# nrf9220_cellrf register map
Vendor: Nordic Semiconductor; Series: nRF92; File version: 1
CPU: CM0 r0p0, little endian, no MPU, no FPU, 2 interrupt priority bits, 33 interrupts
Registers are 32-bit, read-write, reset 0x0 unless marked. A register's access mark holds for its fields unless they carry their own. Offsets are from the block's base; [hi:lo] are bit positions; {n}, {i} and the like mark numbered series; 'fields as' and 'values as' point back to an identical list.

## RXDFE (part 1 of 2) — HALTI_RX_register_map AhmaRx Digital control register map Karhu Rx Analog control register map AhmaRx Digital control register map
Base 0x46130000
0x00 TASKS_RX_START_DIG wo — Starts RX digital filtering.
  [0] TASKS_RX_START_DIG
    1=Trigger task
0x04 TASKS_RX_STOP_DIG wo — Stops RX digital filtering.
  [0] TASKS_RX_STOP_DIG
    1=Trigger task
0x08 TASKS_RX_START_DATA wo — Starts data transfer.
  [0] TASKS_RX_START_DATA
    1=Trigger task
0x0C TASKS_RX_STOP_DATA wo — Stops data transfer.
  [0] TASKS_RX_STOP_DATA
    1=Trigger task
0x10 TASKS_RX_START_NBPM wo — Starts narrow band power measurement.
  [0] TASKS_RX_START_NBPM
    1=Trigger task
0x14 TASKS_RX_START_WBPM wo — Starts wide band power measurement.
  [0] TASKS_RX_START_WBPM
    1=Trigger task
0x18 TASKS_RX_CAPT_SAMPLE_CNT_0 wo — Captures sample counter value to RX_SAMPLE_CNT_CAPT_0 register.
  [0] TASKS_RX_CAPT_SAMPLE_CNT_0
    1=Trigger task
0x1C TASKS_RX_CAPT_SAMPLE_CNT_1 wo — Captures sample counter value to RX_SAMPLE_CNT_CAPT_1 register.
  [0] TASKS_RX_CAPT_SAMPLE_CNT_1
    1=Trigger task
0x20 TASKS_RX_LATCHREADREG wo — Latches set of read-only registers.
  [0] TASKS_RX_LATCHREADREG
    1=Trigger task
0x24 TASKS_WIFI_CLEARIQENERGYDET wo — Clears the IQ energy detect signal monitoring flip-flop.
  [0] TASKS_WIFI_CLEARIQENERGYDET
    1=Trigger task
0x28 TASKS_WIFI_CLEARSIGNALDETGN wo — Clears the Wi-Fi g/n signal detect signal monitoring flip-flop.
  [0] TASKS_WIFI_CLEARSIGNALDETGN
    1=Trigger task
0x2C TASKS_WIFI_CLEARSIGNALDETB wo — Clears the Wi-Fi b signal detect signal monitoring flip-flop.
  [0] TASKS_WIFI_CLEARSIGNALDETB
    1=Trigger task
0x30 TASKS_WIFI_CLEARSIGNALDET wo — Clears the Wi-Fi signal detect signal monitoring flip-flop.
  [0] TASKS_WIFI_CLEARSIGNALDET
    1=Trigger task
0x34 TASKS_WIFI_CLEARRFGAINDOWN wo — Clears the RF gain down signal monitoring flip-flop.
  [0] TASKS_WIFI_CLEARRFGAINDOWN
    1=Trigger task
0x38 TASKS_WIFI_SNAPSHOTIQENERGYDET wo — Takes a snapshot of the IQ energy detect signal.
  [0] TASKS_WIFI_SNAPSHOTIQENERGYDET
    1=Trigger task
0x3C TASKS_WIFI_SNAPSHOTSIGNALDETGN wo — Takes a snapshot of the Wi-Fi g/n signal detect signal.
  [0] TASKS_WIFI_SNAPSHOTSIGNALDETGN
    1=Trigger task
0x40 TASKS_WIFI_SNAPSHOTSIGNALDETB wo — Takes a snapshot of the Wi-Fi b signal detect signal.
  [0] TASKS_WIFI_SNAPSHOTSIGNALDETB
    1=Trigger task
0x44 TASKS_WIFI_SNAPSHOTSIGNALDET wo — Takes a snapshot of the Wi-Fi signal detect signal.
  [0] TASKS_WIFI_SNAPSHOTSIGNALDET
    1=Trigger task
0x48 TASKS_WIFI_SNAPSHOTRFGAINDOWN wo — Takes a snapshot of the RF gain down signal.
  [0] TASKS_WIFI_SNAPSHOTRFGAINDOWN
    1=Trigger task
0x4C TASKS_WIFI_CLEARIQSYNCDET wo — Clears the IQ sync detect signal monitoring flip-flop.
  [0] TASKS_WIFI_CLEARIQSYNCDET
    1=Trigger task
0x50 TASKS_WIFI_SNAPSHOTIQSYNCDET wo — Takes a snapshot of the IQ sync detect signal.
  [0] TASKS_WIFI_SNAPSHOTIQSYNCDET
    1=Trigger task
0x54 TASKS_WIFI_CLEARIQSYNCMAX wo — Clears the max value of IQ sync.
  [0] TASKS_WIFI_CLEARIQSYNCMAX
    1=Trigger task
0x58 TASKS_RX_CAPT_SAMPLE_CNT_2 wo — Captures sample counter value to RX_SAMPLE_CNT_CAPT_2 register.
  [0] TASKS_RX_CAPT_SAMPLE_CNT_2
    1=Trigger task
0x5C TASKS_RX_CAPT_SAMPLE_CNT_3 wo — Captures sample counter value to RX_SAMPLE_CNT_CAPT_3 register.
  [0] TASKS_RX_CAPT_SAMPLE_CNT_3
    1=Trigger task
0x60 TASKS_RX_STOP_NBPM wo — Stops narrow band power measurement.
  [0] TASKS_RX_STOP_NBPM
    1=Trigger task
0x64 TASKS_RX_STOP_WBPM wo — Stops wide band power measurement.
  [0] TASKS_RX_STOP_WBPM
    1=Trigger task
0x68 TASKS_WIFI_CLEARIQENERGYDETWB wo — Clears the wide band IQ energy detect signal monitoring flip-flop.
  [0] TASKS_WIFI_CLEARIQENERGYDETWB
    1=Trigger task
0x6C TASKS_WIFI_SNAPSHOTIQENERGYDETWB wo — Takes a snapshot of the wide band IQ energy detect signal.
  [0] TASKS_WIFI_SNAPSHOTIQENERGYDETWB
    1=Trigger task
0x78 TASKS_WIFI_STARTDATAB wo — Starts RX Wi-Fi b data transfer.
  [0] TASKS_WIFI_STARTDATAB
    1=Trigger task
0x7C TASKS_WIFI_STOPDATAB wo — Stops RX Wi-Fi b data transfer.
  [0] TASKS_WIFI_STOPDATAB
    1=Trigger task
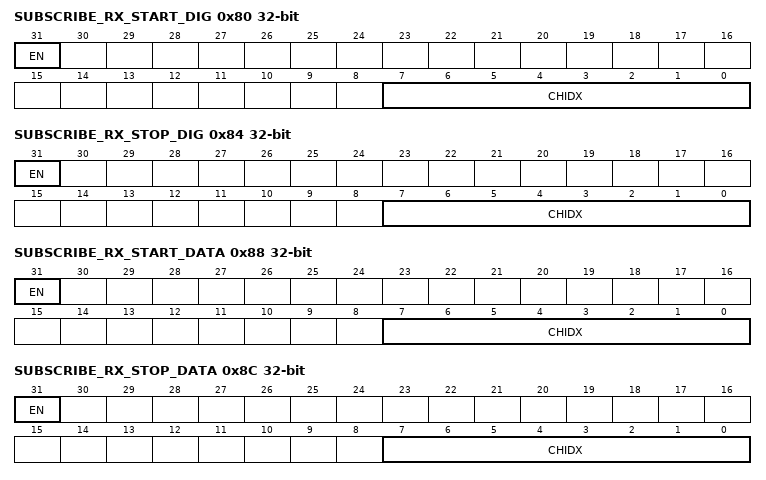
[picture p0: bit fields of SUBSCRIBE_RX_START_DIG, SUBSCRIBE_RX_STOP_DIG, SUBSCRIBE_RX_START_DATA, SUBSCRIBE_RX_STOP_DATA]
0x80 SUBSCRIBE_RX_START_DIG — Subscribe configuration for task RX_START_DIG
  [31] EN
    0=Disabled (Disable subscription); 1=Enabled (Enable subscription)
  [7:0] CHIDX — DPPI channel that task RX_START_DIG will subscribe to
0x84 SUBSCRIBE_RX_STOP_DIG — Subscribe configuration for task RX_STOP_DIG
  [31] EN
    values as SUBSCRIBE_RX_START_DIG.EN
  [7:0] CHIDX — DPPI channel that task RX_STOP_DIG will subscribe to
0x88 SUBSCRIBE_RX_START_DATA — Subscribe configuration for task RX_START_DATA
  [31] EN
    values as SUBSCRIBE_RX_START_DIG.EN
  [7:0] CHIDX — DPPI channel that task RX_START_DATA will subscribe to
0x8C SUBSCRIBE_RX_STOP_DATA — Subscribe configuration for task RX_STOP_DATA
  [31] EN
    values as SUBSCRIBE_RX_START_DIG.EN
  [7:0] CHIDX — DPPI channel that task RX_STOP_DATA will subscribe to
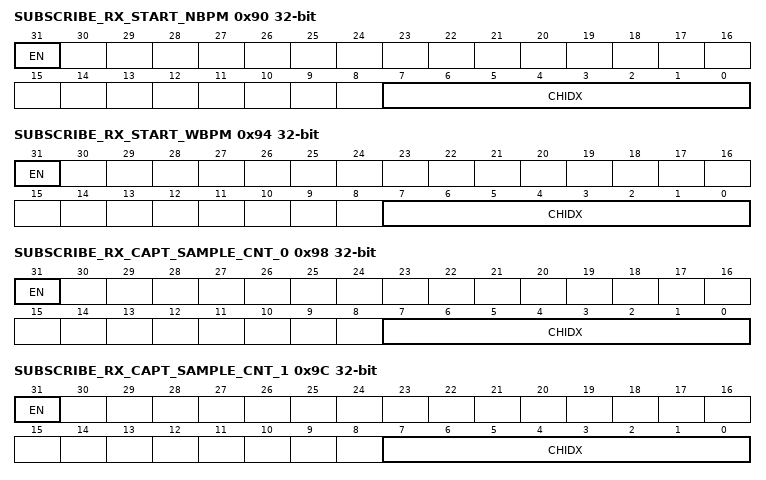
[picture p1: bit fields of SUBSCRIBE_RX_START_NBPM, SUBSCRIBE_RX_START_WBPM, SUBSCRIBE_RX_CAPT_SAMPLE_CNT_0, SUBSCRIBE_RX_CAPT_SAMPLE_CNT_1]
0x90 SUBSCRIBE_RX_START_NBPM — Subscribe configuration for task RX_START_NBPM
  [31] EN
    values as SUBSCRIBE_RX_START_DIG.EN
  [7:0] CHIDX — DPPI channel that task RX_START_NBPM will subscribe to
0x94 SUBSCRIBE_RX_START_WBPM — Subscribe configuration for task RX_START_WBPM
  [31] EN
    values as SUBSCRIBE_RX_START_DIG.EN
  [7:0] CHIDX — DPPI channel that task RX_START_WBPM will subscribe to
0x98 SUBSCRIBE_RX_CAPT_SAMPLE_CNT_0 — Subscribe configuration for task RX_CAPT_SAMPLE_CNT_0
  [31] EN
    values as SUBSCRIBE_RX_START_DIG.EN
  [7:0] CHIDX — DPPI channel that task RX_CAPT_SAMPLE_CNT_0 will subscribe to
0x9C SUBSCRIBE_RX_CAPT_SAMPLE_CNT_1 — Subscribe configuration for task RX_CAPT_SAMPLE_CNT_1
  [31] EN
    values as SUBSCRIBE_RX_START_DIG.EN
  [7:0] CHIDX — DPPI channel that task RX_CAPT_SAMPLE_CNT_1 will subscribe to
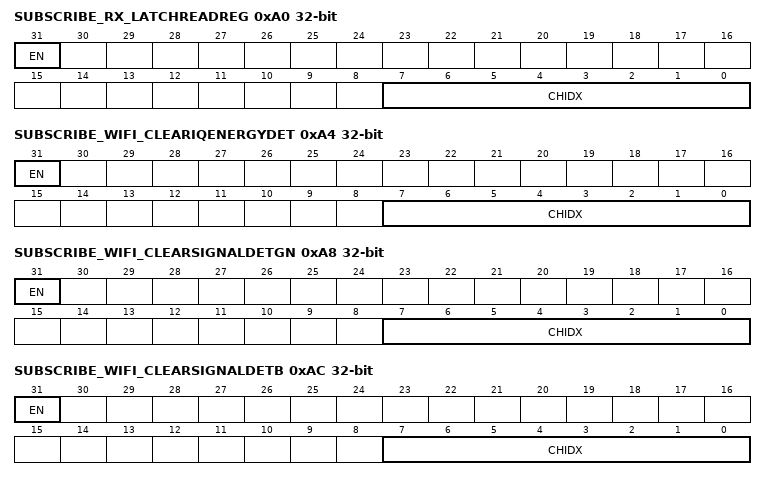
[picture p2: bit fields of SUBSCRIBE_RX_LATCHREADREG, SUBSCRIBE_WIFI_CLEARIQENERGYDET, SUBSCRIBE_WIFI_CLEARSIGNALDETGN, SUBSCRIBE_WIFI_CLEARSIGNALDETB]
0xA0 SUBSCRIBE_RX_LATCHREADREG — Subscribe configuration for task RX_LATCHREADREG
  [31] EN
    values as SUBSCRIBE_RX_START_DIG.EN
  [7:0] CHIDX — DPPI channel that task RX_LATCHREADREG will subscribe to
0xA4 SUBSCRIBE_WIFI_CLEARIQENERGYDET — Subscribe configuration for task WIFI_CLEARIQENERGYDET
  [31] EN
    values as SUBSCRIBE_RX_START_DIG.EN
  [7:0] CHIDX — DPPI channel that task WIFI_CLEARIQENERGYDET will subscribe to
0xA8 SUBSCRIBE_WIFI_CLEARSIGNALDETGN — Subscribe configuration for task WIFI_CLEARSIGNALDETGN
  [31] EN
    values as SUBSCRIBE_RX_START_DIG.EN
  [7:0] CHIDX — DPPI channel that task WIFI_CLEARSIGNALDETGN will subscribe to
0xAC SUBSCRIBE_WIFI_CLEARSIGNALDETB — Subscribe configuration for task WIFI_CLEARSIGNALDETB
  [31] EN
    values as SUBSCRIBE_RX_START_DIG.EN
  [7:0] CHIDX — DPPI channel that task WIFI_CLEARSIGNALDETB will subscribe to
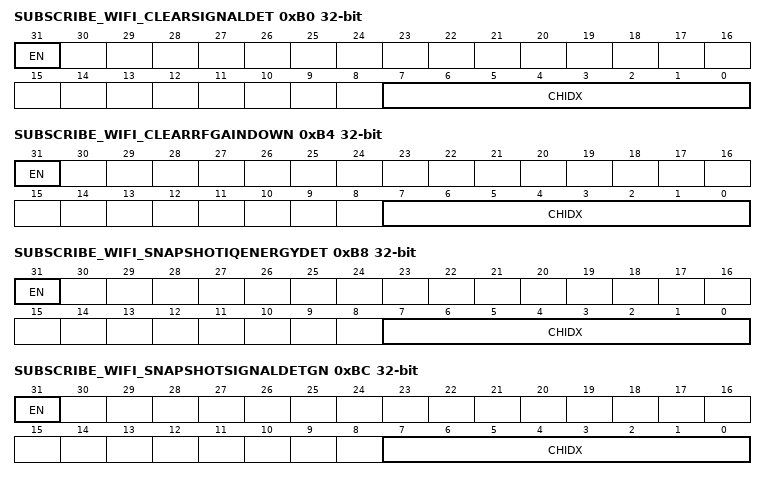
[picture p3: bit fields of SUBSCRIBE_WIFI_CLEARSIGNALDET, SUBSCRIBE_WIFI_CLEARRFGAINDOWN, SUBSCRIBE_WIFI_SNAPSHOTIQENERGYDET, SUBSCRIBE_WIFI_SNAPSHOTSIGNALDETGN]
0xB0 SUBSCRIBE_WIFI_CLEARSIGNALDET — Subscribe configuration for task WIFI_CLEARSIGNALDET
  [31] EN
    values as SUBSCRIBE_RX_START_DIG.EN
  [7:0] CHIDX — DPPI channel that task WIFI_CLEARSIGNALDET will subscribe to
0xB4 SUBSCRIBE_WIFI_CLEARRFGAINDOWN — Subscribe configuration for task WIFI_CLEARRFGAINDOWN
  [31] EN
    values as SUBSCRIBE_RX_START_DIG.EN
  [7:0] CHIDX — DPPI channel that task WIFI_CLEARRFGAINDOWN will subscribe to
0xB8 SUBSCRIBE_WIFI_SNAPSHOTIQENERGYDET — Subscribe configuration for task WIFI_SNAPSHOTIQENERGYDET
  [31] EN
    values as SUBSCRIBE_RX_START_DIG.EN
  [7:0] CHIDX — DPPI channel that task WIFI_SNAPSHOTIQENERGYDET will subscribe to
0xBC SUBSCRIBE_WIFI_SNAPSHOTSIGNALDETGN — Subscribe configuration for task WIFI_SNAPSHOTSIGNALDETGN
  [31] EN
    values as SUBSCRIBE_RX_START_DIG.EN
  [7:0] CHIDX — DPPI channel that task WIFI_SNAPSHOTSIGNALDETGN will subscribe to
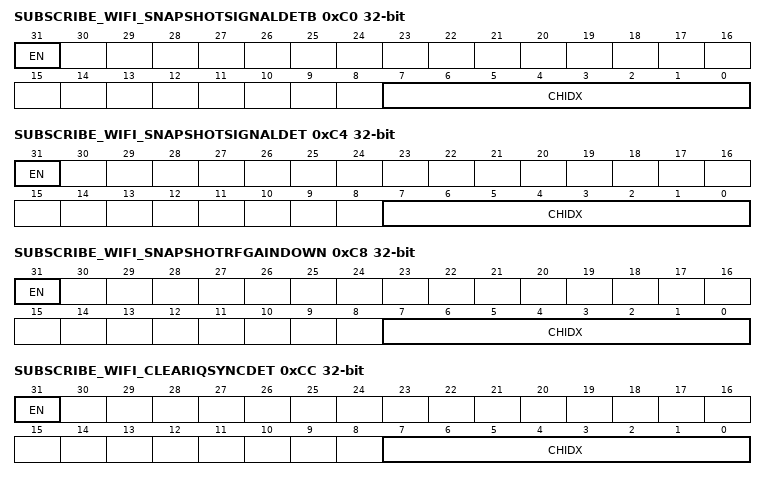
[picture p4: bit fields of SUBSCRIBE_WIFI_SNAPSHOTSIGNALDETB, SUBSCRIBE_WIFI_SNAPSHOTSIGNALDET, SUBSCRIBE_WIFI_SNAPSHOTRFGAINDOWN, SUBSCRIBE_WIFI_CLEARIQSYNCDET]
0xC0 SUBSCRIBE_WIFI_SNAPSHOTSIGNALDETB — Subscribe configuration for task WIFI_SNAPSHOTSIGNALDETB
  [31] EN
    values as SUBSCRIBE_RX_START_DIG.EN
  [7:0] CHIDX — DPPI channel that task WIFI_SNAPSHOTSIGNALDETB will subscribe to
0xC4 SUBSCRIBE_WIFI_SNAPSHOTSIGNALDET — Subscribe configuration for task WIFI_SNAPSHOTSIGNALDET
  [31] EN
    values as SUBSCRIBE_RX_START_DIG.EN
  [7:0] CHIDX — DPPI channel that task WIFI_SNAPSHOTSIGNALDET will subscribe to
0xC8 SUBSCRIBE_WIFI_SNAPSHOTRFGAINDOWN — Subscribe configuration for task WIFI_SNAPSHOTRFGAINDOWN
  [31] EN
    values as SUBSCRIBE_RX_START_DIG.EN
  [7:0] CHIDX — DPPI channel that task WIFI_SNAPSHOTRFGAINDOWN will subscribe to
0xCC SUBSCRIBE_WIFI_CLEARIQSYNCDET — Subscribe configuration for task WIFI_CLEARIQSYNCDET
  [31] EN
    values as SUBSCRIBE_RX_START_DIG.EN
  [7:0] CHIDX — DPPI channel that task WIFI_CLEARIQSYNCDET will subscribe to
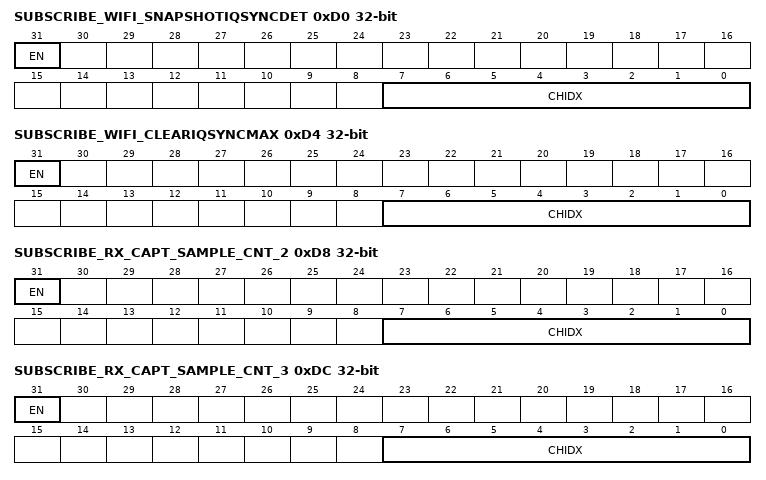
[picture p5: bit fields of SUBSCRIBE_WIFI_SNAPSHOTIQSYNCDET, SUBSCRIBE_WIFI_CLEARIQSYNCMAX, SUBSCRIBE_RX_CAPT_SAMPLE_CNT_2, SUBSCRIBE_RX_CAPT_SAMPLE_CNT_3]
0xD0 SUBSCRIBE_WIFI_SNAPSHOTIQSYNCDET — Subscribe configuration for task WIFI_SNAPSHOTIQSYNCDET
  [31] EN
    values as SUBSCRIBE_RX_START_DIG.EN
  [7:0] CHIDX — DPPI channel that task WIFI_SNAPSHOTIQSYNCDET will subscribe to
0xD4 SUBSCRIBE_WIFI_CLEARIQSYNCMAX — Subscribe configuration for task WIFI_CLEARIQSYNCMAX
  [31] EN
    values as SUBSCRIBE_RX_START_DIG.EN
  [7:0] CHIDX — DPPI channel that task WIFI_CLEARIQSYNCMAX will subscribe to
0xD8 SUBSCRIBE_RX_CAPT_SAMPLE_CNT_2 — Subscribe configuration for task RX_CAPT_SAMPLE_CNT_2
  [31] EN
    values as SUBSCRIBE_RX_START_DIG.EN
  [7:0] CHIDX — DPPI channel that task RX_CAPT_SAMPLE_CNT_2 will subscribe to
0xDC SUBSCRIBE_RX_CAPT_SAMPLE_CNT_3 — Subscribe configuration for task RX_CAPT_SAMPLE_CNT_3
  [31] EN
    values as SUBSCRIBE_RX_START_DIG.EN
  [7:0] CHIDX — DPPI channel that task RX_CAPT_SAMPLE_CNT_3 will subscribe to
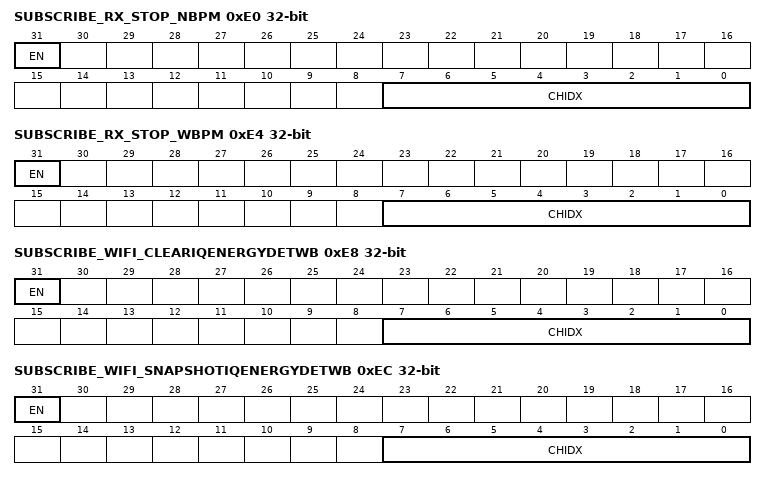
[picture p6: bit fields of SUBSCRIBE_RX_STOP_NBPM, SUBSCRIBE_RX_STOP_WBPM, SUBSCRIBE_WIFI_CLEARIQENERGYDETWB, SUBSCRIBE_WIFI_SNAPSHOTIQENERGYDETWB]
0xE0 SUBSCRIBE_RX_STOP_NBPM — Subscribe configuration for task RX_STOP_NBPM
  [31] EN
    values as SUBSCRIBE_RX_START_DIG.EN
  [7:0] CHIDX — DPPI channel that task RX_STOP_NBPM will subscribe to
0xE4 SUBSCRIBE_RX_STOP_WBPM — Subscribe configuration for task RX_STOP_WBPM
  [31] EN
    values as SUBSCRIBE_RX_START_DIG.EN
  [7:0] CHIDX — DPPI channel that task RX_STOP_WBPM will subscribe to
0xE8 SUBSCRIBE_WIFI_CLEARIQENERGYDETWB — Subscribe configuration for task WIFI_CLEARIQENERGYDETWB
  [31] EN
    values as SUBSCRIBE_RX_START_DIG.EN
  [7:0] CHIDX — DPPI channel that task WIFI_CLEARIQENERGYDETWB will subscribe to
0xEC SUBSCRIBE_WIFI_SNAPSHOTIQENERGYDETWB — Subscribe configuration for task WIFI_SNAPSHOTIQENERGYDETWB
  [31] EN
    values as SUBSCRIBE_RX_START_DIG.EN
  [7:0] CHIDX — DPPI channel that task WIFI_SNAPSHOTIQENERGYDETWB will subscribe to
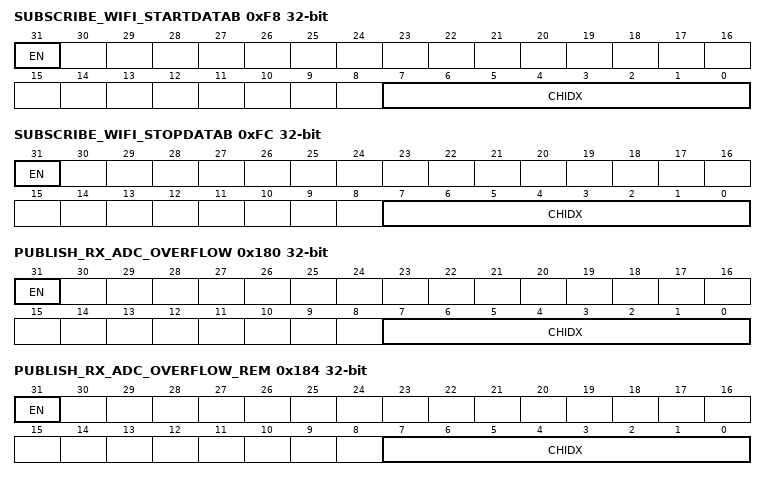
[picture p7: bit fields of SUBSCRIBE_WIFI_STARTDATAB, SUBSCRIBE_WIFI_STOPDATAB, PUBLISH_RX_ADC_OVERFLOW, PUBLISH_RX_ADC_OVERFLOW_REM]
0xF8 SUBSCRIBE_WIFI_STARTDATAB — Subscribe configuration for task WIFI_STARTDATAB
  [31] EN
    values as SUBSCRIBE_RX_START_DIG.EN
  [7:0] CHIDX — DPPI channel that task WIFI_STARTDATAB will subscribe to
0xFC SUBSCRIBE_WIFI_STOPDATAB — Subscribe configuration for task WIFI_STOPDATAB
  [31] EN
    values as SUBSCRIBE_RX_START_DIG.EN
  [7:0] CHIDX — DPPI channel that task WIFI_STOPDATAB will subscribe to
0x100 EVENTS_RX_ADC_OVERFLOW — ADC overflow occurred.
  [0] EVENTS_RX_ADC_OVERFLOW
    0=NotGenerated (Event not generated); 1=Generated (Event generated)
0x104 EVENTS_RX_ADC_OVERFLOW_REM — ADC overflow removed.
  [0] EVENTS_RX_ADC_OVERFLOW_REM
    values as EVENTS_RX_ADC_OVERFLOW.EVENTS_RX_ADC_OVERFLOW
0x108 EVENTS_RX_NBPM_READY — Narrow band power measuremnt ready.
  [0] EVENTS_RX_NBPM_READY
    values as EVENTS_RX_ADC_OVERFLOW.EVENTS_RX_ADC_OVERFLOW
0x10C EVENTS_RX_WBPM_READY — Wide band power measuremnt ready.
  [0] EVENTS_RX_WBPM_READY
    values as EVENTS_RX_ADC_OVERFLOW.EVENTS_RX_ADC_OVERFLOW
0x110 EVENTS_RX_SAMPLE_CNT_COMP_0 — RX sample count matches to value in RX_SAMPLE_CNT_COMP_0 register.
  [0] EVENTS_RX_SAMPLE_CNT_COMP_0
    values as EVENTS_RX_ADC_OVERFLOW.EVENTS_RX_ADC_OVERFLOW
0x114 EVENTS_RX_SAMPLE_CNT_COMP_1 — RX sample count matches to value in RX_SAMPLE_CNT_COMP_1 register.
  [0] EVENTS_RX_SAMPLE_CNT_COMP_1
    values as EVENTS_RX_ADC_OVERFLOW.EVENTS_RX_ADC_OVERFLOW
0x118 EVENTS_RX_SAMPLE_CNT_WRAP — RX sample counter wraps.
  [0] EVENTS_RX_SAMPLE_CNT_WRAP
    values as EVENTS_RX_ADC_OVERFLOW.EVENTS_RX_ADC_OVERFLOW
0x11C EVENTS_RX_DATA_OVERFLOW — RX data overflow occurred.
  [0] EVENTS_RX_DATA_OVERFLOW
    values as EVENTS_RX_ADC_OVERFLOW.EVENTS_RX_ADC_OVERFLOW
0x120 EVENTS_RX_SAMPLE_CNT_CAPT_0 — RX sample count value is captured to RX_SAMPLE_CNT_CAPT_0 register.
  [0] EVENTS_RX_SAMPLE_CNT_CAPT_0
    values as EVENTS_RX_ADC_OVERFLOW.EVENTS_RX_ADC_OVERFLOW
0x124 EVENTS_RX_SAMPLE_CNT_CAPT_1 — RX sample count value is captured to RX_SAMPLE_CNT_CAPT_1 register.
  [0] EVENTS_RX_SAMPLE_CNT_CAPT_1
    values as EVENTS_RX_ADC_OVERFLOW.EVENTS_RX_ADC_OVERFLOW
0x128 EVENTS_RX_READREGLATCHED — Set of read-only registers lacthed.
  [0] EVENTS_RX_READREGLATCHED
    values as EVENTS_RX_ADC_OVERFLOW.EVENTS_RX_ADC_OVERFLOW
0x12C EVENTS_WIFI_IQENERGYDET — IQ energy detected.
  [0] EVENTS_WIFI_IQENERGYDET
    values as EVENTS_RX_ADC_OVERFLOW.EVENTS_RX_ADC_OVERFLOW
0x130 EVENTS_WIFI_SIGNALDETGN — Wi-Fi g/n signal detected
  [0] EVENTS_WIFI_SIGNALDETGN
    values as EVENTS_RX_ADC_OVERFLOW.EVENTS_RX_ADC_OVERFLOW
0x134 EVENTS_WIFI_SIGNALDETB — Wi-Fi b signal detected
  [0] EVENTS_WIFI_SIGNALDETB
    values as EVENTS_RX_ADC_OVERFLOW.EVENTS_RX_ADC_OVERFLOW
0x138 EVENTS_WIFI_SIGNALDET — Wi-Fi signal detected
  [0] EVENTS_WIFI_SIGNALDET
    values as EVENTS_RX_ADC_OVERFLOW.EVENTS_RX_ADC_OVERFLOW
0x13C EVENTS_WIFI_RFGAINDOWN — RF gain down.
  [0] EVENTS_WIFI_RFGAINDOWN
    values as EVENTS_RX_ADC_OVERFLOW.EVENTS_RX_ADC_OVERFLOW
0x140 EVENTS_WIFI_DATAOVERFLOWGN — Wi-Fi g/n data overflow.
  [0] EVENTS_WIFI_DATAOVERFLOWGN
    values as EVENTS_RX_ADC_OVERFLOW.EVENTS_RX_ADC_OVERFLOW
0x144 EVENTS_WIFI_DATAOVERFLOWB — Wi-Fi b data overflow.
  [0] EVENTS_WIFI_DATAOVERFLOWB
    values as EVENTS_RX_ADC_OVERFLOW.EVENTS_RX_ADC_OVERFLOW
0x148 EVENTS_WIFI_IQSYNCDET — IQ sync detected
  [0] EVENTS_WIFI_IQSYNCDET
    values as EVENTS_RX_ADC_OVERFLOW.EVENTS_RX_ADC_OVERFLOW
0x14C EVENTS_RX_SAMPLE_CNT_CAPT_2 — RX sample count value is captured to RX_SAMPLE_CNT_CAPT_2 register.
  [0] EVENTS_RX_SAMPLE_CNT_CAPT_2
    values as EVENTS_RX_ADC_OVERFLOW.EVENTS_RX_ADC_OVERFLOW
0x150 EVENTS_RX_SAMPLE_CNT_CAPT_3 — RX sample count value is captured to RX_SAMPLE_CNT_CAPT_3 register.
  [0] EVENTS_RX_SAMPLE_CNT_CAPT_3
    values as EVENTS_RX_ADC_OVERFLOW.EVENTS_RX_ADC_OVERFLOW
0x154 EVENTS_WIFI_IQENERGYDETWB — Wide band IQ energy detected.
  [0] EVENTS_WIFI_IQENERGYDETWB
    values as EVENTS_RX_ADC_OVERFLOW.EVENTS_RX_ADC_OVERFLOW
0x180 PUBLISH_RX_ADC_OVERFLOW — Publish configuration for event RX_ADC_OVERFLOW
  [31] EN
    0=Disabled (Disable publishing); 1=Enabled (Enable publishing)
  [7:0] CHIDX — DPPI channel that event RX_ADC_OVERFLOW will publish to
0x184 PUBLISH_RX_ADC_OVERFLOW_REM — Publish configuration for event RX_ADC_OVERFLOW_REM
  [31] EN
    values as PUBLISH_RX_ADC_OVERFLOW.EN
  [7:0] CHIDX — DPPI channel that event RX_ADC_OVERFLOW_REM will publish to
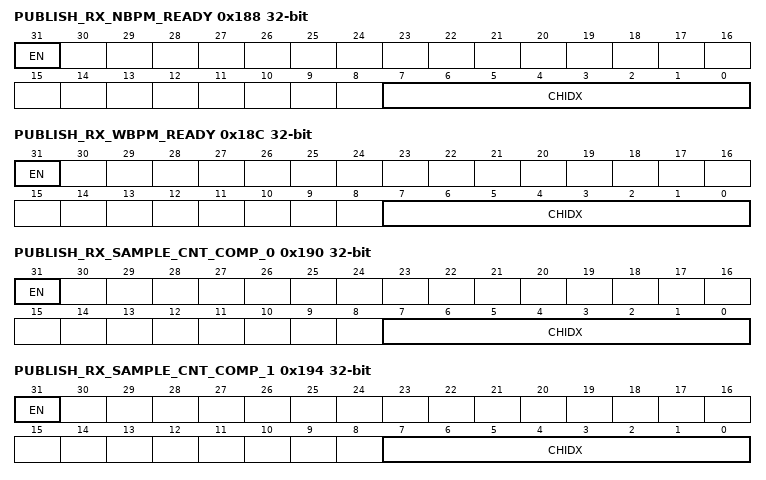
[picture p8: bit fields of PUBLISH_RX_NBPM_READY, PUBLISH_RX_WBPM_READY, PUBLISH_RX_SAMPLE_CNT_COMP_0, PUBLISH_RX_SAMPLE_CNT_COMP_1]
0x188 PUBLISH_RX_NBPM_READY — Publish configuration for event RX_NBPM_READY
  [31] EN
    values as PUBLISH_RX_ADC_OVERFLOW.EN
  [7:0] CHIDX — DPPI channel that event RX_NBPM_READY will publish to
0x18C PUBLISH_RX_WBPM_READY — Publish configuration for event RX_WBPM_READY
  [31] EN
    values as PUBLISH_RX_ADC_OVERFLOW.EN
  [7:0] CHIDX — DPPI channel that event RX_WBPM_READY will publish to
0x190 PUBLISH_RX_SAMPLE_CNT_COMP_0 — Publish configuration for event RX_SAMPLE_CNT_COMP_0
  [31] EN
    values as PUBLISH_RX_ADC_OVERFLOW.EN
  [7:0] CHIDX — DPPI channel that event RX_SAMPLE_CNT_COMP_0 will publish to
0x194 PUBLISH_RX_SAMPLE_CNT_COMP_1 — Publish configuration for event RX_SAMPLE_CNT_COMP_1
  [31] EN
    values as PUBLISH_RX_ADC_OVERFLOW.EN
  [7:0] CHIDX — DPPI channel that event RX_SAMPLE_CNT_COMP_1 will publish to
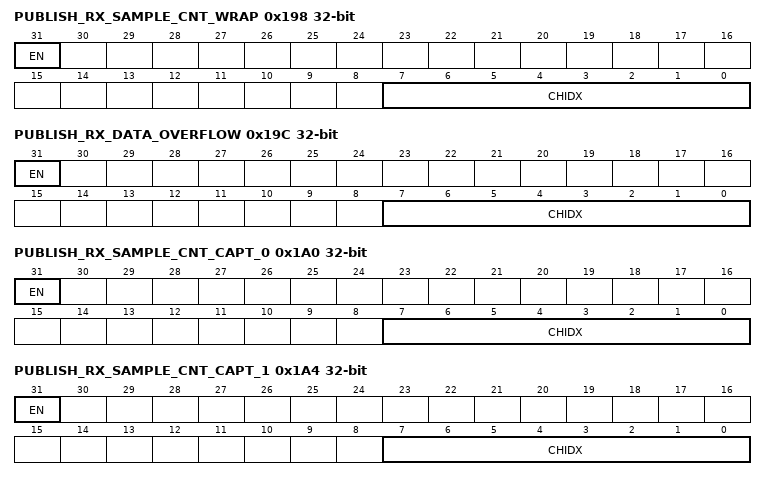
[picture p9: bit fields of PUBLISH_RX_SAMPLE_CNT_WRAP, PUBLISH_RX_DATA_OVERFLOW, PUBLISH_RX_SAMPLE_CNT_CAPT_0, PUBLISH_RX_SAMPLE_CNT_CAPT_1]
0x198 PUBLISH_RX_SAMPLE_CNT_WRAP — Publish configuration for event RX_SAMPLE_CNT_WRAP
  [31] EN
    values as PUBLISH_RX_ADC_OVERFLOW.EN
  [7:0] CHIDX — DPPI channel that event RX_SAMPLE_CNT_WRAP will publish to
0x19C PUBLISH_RX_DATA_OVERFLOW — Publish configuration for event RX_DATA_OVERFLOW
  [31] EN
    values as PUBLISH_RX_ADC_OVERFLOW.EN
  [7:0] CHIDX — DPPI channel that event RX_DATA_OVERFLOW will publish to
0x1A0 PUBLISH_RX_SAMPLE_CNT_CAPT_0 — Publish configuration for event RX_SAMPLE_CNT_CAPT_0
  [31] EN
    values as PUBLISH_RX_ADC_OVERFLOW.EN
  [7:0] CHIDX — DPPI channel that event RX_SAMPLE_CNT_CAPT_0 will publish to
0x1A4 PUBLISH_RX_SAMPLE_CNT_CAPT_1 — Publish configuration for event RX_SAMPLE_CNT_CAPT_1
  [31] EN
    values as PUBLISH_RX_ADC_OVERFLOW.EN
  [7:0] CHIDX — DPPI channel that event RX_SAMPLE_CNT_CAPT_1 will publish to
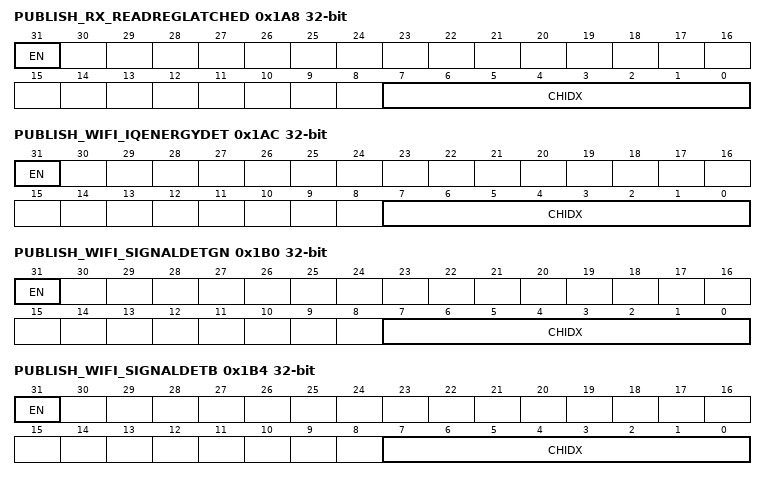
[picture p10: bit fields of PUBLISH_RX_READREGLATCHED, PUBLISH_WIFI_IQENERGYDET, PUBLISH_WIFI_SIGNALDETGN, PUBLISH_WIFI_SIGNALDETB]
0x1A8 PUBLISH_RX_READREGLATCHED — Publish configuration for event RX_READREGLATCHED
  [31] EN
    values as PUBLISH_RX_ADC_OVERFLOW.EN
  [7:0] CHIDX — DPPI channel that event RX_READREGLATCHED will publish to
0x1AC PUBLISH_WIFI_IQENERGYDET — Publish configuration for event WIFI_IQENERGYDET
  [31] EN
    values as PUBLISH_RX_ADC_OVERFLOW.EN
  [7:0] CHIDX — DPPI channel that event WIFI_IQENERGYDET will publish to
0x1B0 PUBLISH_WIFI_SIGNALDETGN — Publish configuration for event WIFI_SIGNALDETGN
  [31] EN
    values as PUBLISH_RX_ADC_OVERFLOW.EN
  [7:0] CHIDX — DPPI channel that event WIFI_SIGNALDETGN will publish to
0x1B4 PUBLISH_WIFI_SIGNALDETB — Publish configuration for event WIFI_SIGNALDETB
  [31] EN
    values as PUBLISH_RX_ADC_OVERFLOW.EN
  [7:0] CHIDX — DPPI channel that event WIFI_SIGNALDETB will publish to
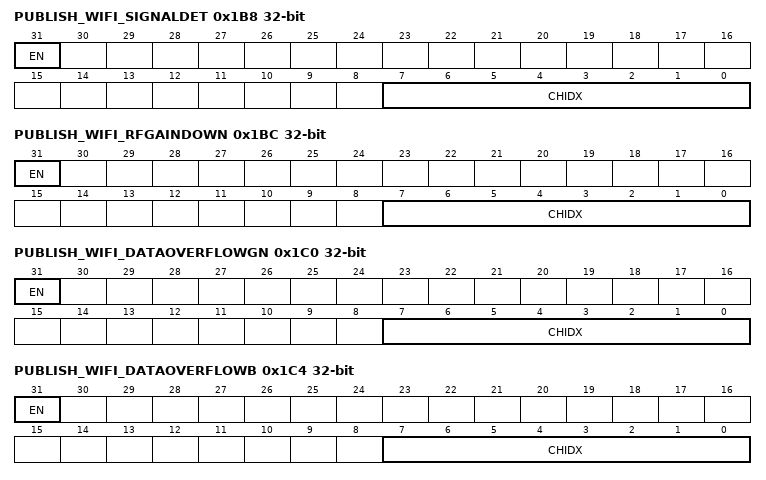
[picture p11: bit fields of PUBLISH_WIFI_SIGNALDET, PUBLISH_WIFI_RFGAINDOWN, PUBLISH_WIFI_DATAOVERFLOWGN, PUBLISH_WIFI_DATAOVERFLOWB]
0x1B8 PUBLISH_WIFI_SIGNALDET — Publish configuration for event WIFI_SIGNALDET
  [31] EN
    values as PUBLISH_RX_ADC_OVERFLOW.EN
  [7:0] CHIDX — DPPI channel that event WIFI_SIGNALDET will publish to
0x1BC PUBLISH_WIFI_RFGAINDOWN — Publish configuration for event WIFI_RFGAINDOWN
  [31] EN
    values as PUBLISH_RX_ADC_OVERFLOW.EN
  [7:0] CHIDX — DPPI channel that event WIFI_RFGAINDOWN will publish to
0x1C0 PUBLISH_WIFI_DATAOVERFLOWGN — Publish configuration for event WIFI_DATAOVERFLOWGN
  [31] EN
    values as PUBLISH_RX_ADC_OVERFLOW.EN
  [7:0] CHIDX — DPPI channel that event WIFI_DATAOVERFLOWGN will publish to
0x1C4 PUBLISH_WIFI_DATAOVERFLOWB — Publish configuration for event WIFI_DATAOVERFLOWB
  [31] EN
    values as PUBLISH_RX_ADC_OVERFLOW.EN
  [7:0] CHIDX — DPPI channel that event WIFI_DATAOVERFLOWB will publish to
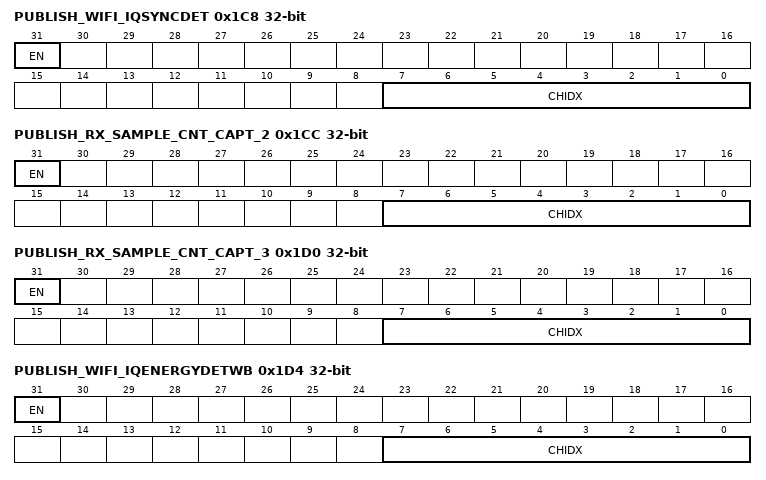
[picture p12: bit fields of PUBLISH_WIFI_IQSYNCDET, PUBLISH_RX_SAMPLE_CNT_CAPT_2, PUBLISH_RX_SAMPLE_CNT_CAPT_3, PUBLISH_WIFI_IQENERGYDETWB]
0x1C8 PUBLISH_WIFI_IQSYNCDET — Publish configuration for event WIFI_IQSYNCDET
  [31] EN
    values as PUBLISH_RX_ADC_OVERFLOW.EN
  [7:0] CHIDX — DPPI channel that event WIFI_IQSYNCDET will publish to
0x1CC PUBLISH_RX_SAMPLE_CNT_CAPT_2 — Publish configuration for event RX_SAMPLE_CNT_CAPT_2
  [31] EN
    values as PUBLISH_RX_ADC_OVERFLOW.EN
  [7:0] CHIDX — DPPI channel that event RX_SAMPLE_CNT_CAPT_2 will publish to
0x1D0 PUBLISH_RX_SAMPLE_CNT_CAPT_3 — Publish configuration for event RX_SAMPLE_CNT_CAPT_3
  [31] EN
    values as PUBLISH_RX_ADC_OVERFLOW.EN
  [7:0] CHIDX — DPPI channel that event RX_SAMPLE_CNT_CAPT_3 will publish to
0x1D4 PUBLISH_WIFI_IQENERGYDETWB — Publish configuration for event WIFI_IQENERGYDETWB
  [31] EN
    values as PUBLISH_RX_ADC_OVERFLOW.EN
  [7:0] CHIDX — DPPI channel that event WIFI_IQENERGYDETWB will publish to
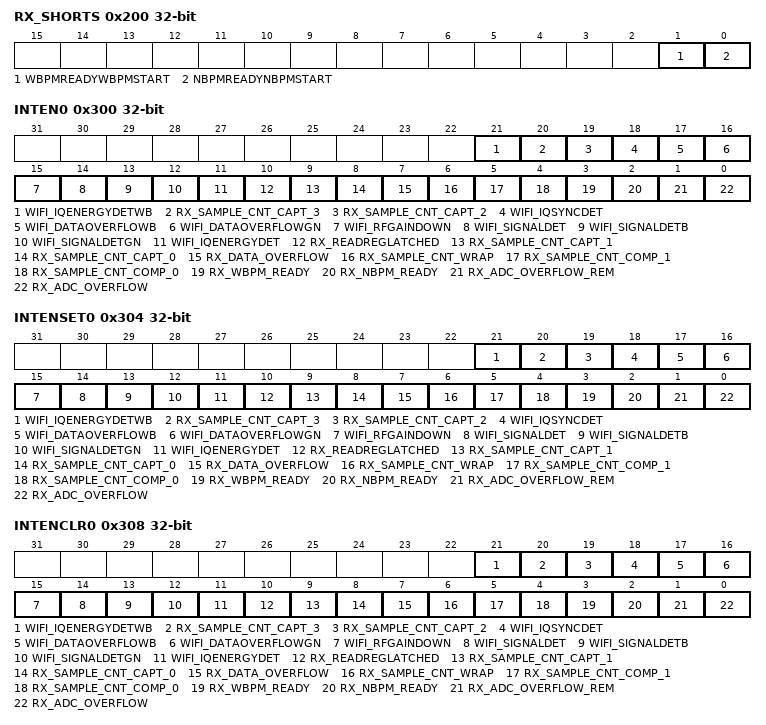
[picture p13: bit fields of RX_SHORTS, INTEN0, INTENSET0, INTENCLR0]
0x200 RX_SHORTS — Shortcuts between local events and tasks.
  [1] WBPMREADYWBPMSTART — Shortcut between event RX_WBPM_READY and task RX_START_WBPM.
    0=Disabled; 1=Enabled
  [0] NBPMREADYNBPMSTART — Shortcut between event RX_NBPM_READY and task RX_START_NBPM.
    0=Disabled; 1=Enabled
0x300 INTEN0 — Enable or disable interrupt
  [all] fields
    0=Disabled; 1=Enabled
  [21] WIFI_IQENERGYDETWB — Enable or disable interrupt for event WIFI_IQENERGYDETWB
  [20] RX_SAMPLE_CNT_CAPT_3 — Enable or disable interrupt for event RX_SAMPLE_CNT_CAPT_3
  [19] RX_SAMPLE_CNT_CAPT_2 — Enable or disable interrupt for event RX_SAMPLE_CNT_CAPT_2
  [18] WIFI_IQSYNCDET — Enable or disable interrupt for event WIFI_IQSYNCDET
  [17] WIFI_DATAOVERFLOWB — Enable or disable interrupt for event WIFI_DATAOVERFLOWB
  [16] WIFI_DATAOVERFLOWGN — Enable or disable interrupt for event WIFI_DATAOVERFLOWGN
  [15] WIFI_RFGAINDOWN — Enable or disable interrupt for event WIFI_RFGAINDOWN
  [14] WIFI_SIGNALDET — Enable or disable interrupt for event WIFI_SIGNALDET
  [13] WIFI_SIGNALDETB — Enable or disable interrupt for event WIFI_SIGNALDETB
  [12] WIFI_SIGNALDETGN — Enable or disable interrupt for event WIFI_SIGNALDETGN
  [11] WIFI_IQENERGYDET — Enable or disable interrupt for event WIFI_IQENERGYDET
  [10] RX_READREGLATCHED — Enable or disable interrupt for event RX_READREGLATCHED
  [9] RX_SAMPLE_CNT_CAPT_1 — Enable or disable interrupt for event RX_SAMPLE_CNT_CAPT_1
  [8] RX_SAMPLE_CNT_CAPT_0 — Enable or disable interrupt for event RX_SAMPLE_CNT_CAPT_0
  [7] RX_DATA_OVERFLOW — Enable or disable interrupt for event RX_DATA_OVERFLOW
  [6] RX_SAMPLE_CNT_WRAP — Enable or disable interrupt for event RX_SAMPLE_CNT_WRAP
  [5] RX_SAMPLE_CNT_COMP_1 — Enable or disable interrupt for event RX_SAMPLE_CNT_COMP_1
  [4] RX_SAMPLE_CNT_COMP_0 — Enable or disable interrupt for event RX_SAMPLE_CNT_COMP_0
  [3] RX_WBPM_READY — Enable or disable interrupt for event RX_WBPM_READY
  [2] RX_NBPM_READY — Enable or disable interrupt for event RX_NBPM_READY
  [1] RX_ADC_OVERFLOW_REM — Enable or disable interrupt for event RX_ADC_OVERFLOW_REM
  [0] RX_ADC_OVERFLOW — Enable or disable interrupt for event RX_ADC_OVERFLOW
0x304 INTENSET0 — Enable interrupt
  [all] fields
    on read: 0=Disabled (Read: Disabled); 1=Enabled (Read: Enabled) | on write: 1=Set (Enable)
  [21] WIFI_IQENERGYDETWB — Write '1' to enable interrupt for event WIFI_IQENERGYDETWB
  [20] RX_SAMPLE_CNT_CAPT_3 — Write '1' to enable interrupt for event RX_SAMPLE_CNT_CAPT_3
  [19] RX_SAMPLE_CNT_CAPT_2 — Write '1' to enable interrupt for event RX_SAMPLE_CNT_CAPT_2
  [18] WIFI_IQSYNCDET — Write '1' to enable interrupt for event WIFI_IQSYNCDET
  [17] WIFI_DATAOVERFLOWB — Write '1' to enable interrupt for event WIFI_DATAOVERFLOWB
  [16] WIFI_DATAOVERFLOWGN — Write '1' to enable interrupt for event WIFI_DATAOVERFLOWGN
  [15] WIFI_RFGAINDOWN — Write '1' to enable interrupt for event WIFI_RFGAINDOWN
  [14] WIFI_SIGNALDET — Write '1' to enable interrupt for event WIFI_SIGNALDET
  [13] WIFI_SIGNALDETB — Write '1' to enable interrupt for event WIFI_SIGNALDETB
  [12] WIFI_SIGNALDETGN — Write '1' to enable interrupt for event WIFI_SIGNALDETGN
  [11] WIFI_IQENERGYDET — Write '1' to enable interrupt for event WIFI_IQENERGYDET
  [10] RX_READREGLATCHED — Write '1' to enable interrupt for event RX_READREGLATCHED
  [9] RX_SAMPLE_CNT_CAPT_1 — Write '1' to enable interrupt for event RX_SAMPLE_CNT_CAPT_1
  [8] RX_SAMPLE_CNT_CAPT_0 — Write '1' to enable interrupt for event RX_SAMPLE_CNT_CAPT_0
  [7] RX_DATA_OVERFLOW — Write '1' to enable interrupt for event RX_DATA_OVERFLOW
  [6] RX_SAMPLE_CNT_WRAP — Write '1' to enable interrupt for event RX_SAMPLE_CNT_WRAP
  [5] RX_SAMPLE_CNT_COMP_1 — Write '1' to enable interrupt for event RX_SAMPLE_CNT_COMP_1
  [4] RX_SAMPLE_CNT_COMP_0 — Write '1' to enable interrupt for event RX_SAMPLE_CNT_COMP_0
  [3] RX_WBPM_READY — Write '1' to enable interrupt for event RX_WBPM_READY
  [2] RX_NBPM_READY — Write '1' to enable interrupt for event RX_NBPM_READY
  [1] RX_ADC_OVERFLOW_REM — Write '1' to enable interrupt for event RX_ADC_OVERFLOW_REM
  [0] RX_ADC_OVERFLOW — Write '1' to enable interrupt for event RX_ADC_OVERFLOW
0x308 INTENCLR0 — Disable interrupt
  [all] fields
    on read: 0=Disabled (Read: Disabled); 1=Enabled (Read: Enabled) | on write: 1=Clear (Disable)
  [21] WIFI_IQENERGYDETWB — Write '1' to disable interrupt for event WIFI_IQENERGYDETWB
  [20] RX_SAMPLE_CNT_CAPT_3 — Write '1' to disable interrupt for event RX_SAMPLE_CNT_CAPT_3
  [19] RX_SAMPLE_CNT_CAPT_2 — Write '1' to disable interrupt for event RX_SAMPLE_CNT_CAPT_2
  [18] WIFI_IQSYNCDET — Write '1' to disable interrupt for event WIFI_IQSYNCDET
  [17] WIFI_DATAOVERFLOWB — Write '1' to disable interrupt for event WIFI_DATAOVERFLOWB
  [16] WIFI_DATAOVERFLOWGN — Write '1' to disable interrupt for event WIFI_DATAOVERFLOWGN
  [15] WIFI_RFGAINDOWN — Write '1' to disable interrupt for event WIFI_RFGAINDOWN
  [14] WIFI_SIGNALDET — Write '1' to disable interrupt for event WIFI_SIGNALDET
  [13] WIFI_SIGNALDETB — Write '1' to disable interrupt for event WIFI_SIGNALDETB
  [12] WIFI_SIGNALDETGN — Write '1' to disable interrupt for event WIFI_SIGNALDETGN
  [11] WIFI_IQENERGYDET — Write '1' to disable interrupt for event WIFI_IQENERGYDET
  [10] RX_READREGLATCHED — Write '1' to disable interrupt for event RX_READREGLATCHED
  [9] RX_SAMPLE_CNT_CAPT_1 — Write '1' to disable interrupt for event RX_SAMPLE_CNT_CAPT_1
  [8] RX_SAMPLE_CNT_CAPT_0 — Write '1' to disable interrupt for event RX_SAMPLE_CNT_CAPT_0
  [7] RX_DATA_OVERFLOW — Write '1' to disable interrupt for event RX_DATA_OVERFLOW
  [6] RX_SAMPLE_CNT_WRAP — Write '1' to disable interrupt for event RX_SAMPLE_CNT_WRAP
  [5] RX_SAMPLE_CNT_COMP_1 — Write '1' to disable interrupt for event RX_SAMPLE_CNT_COMP_1
  [4] RX_SAMPLE_CNT_COMP_0 — Write '1' to disable interrupt for event RX_SAMPLE_CNT_COMP_0
  [3] RX_WBPM_READY — Write '1' to disable interrupt for event RX_WBPM_READY
  [2] RX_NBPM_READY — Write '1' to disable interrupt for event RX_NBPM_READY
  [1] RX_ADC_OVERFLOW_REM — Write '1' to disable interrupt for event RX_ADC_OVERFLOW_REM
  [0] RX_ADC_OVERFLOW — Write '1' to disable interrupt for event RX_ADC_OVERFLOW
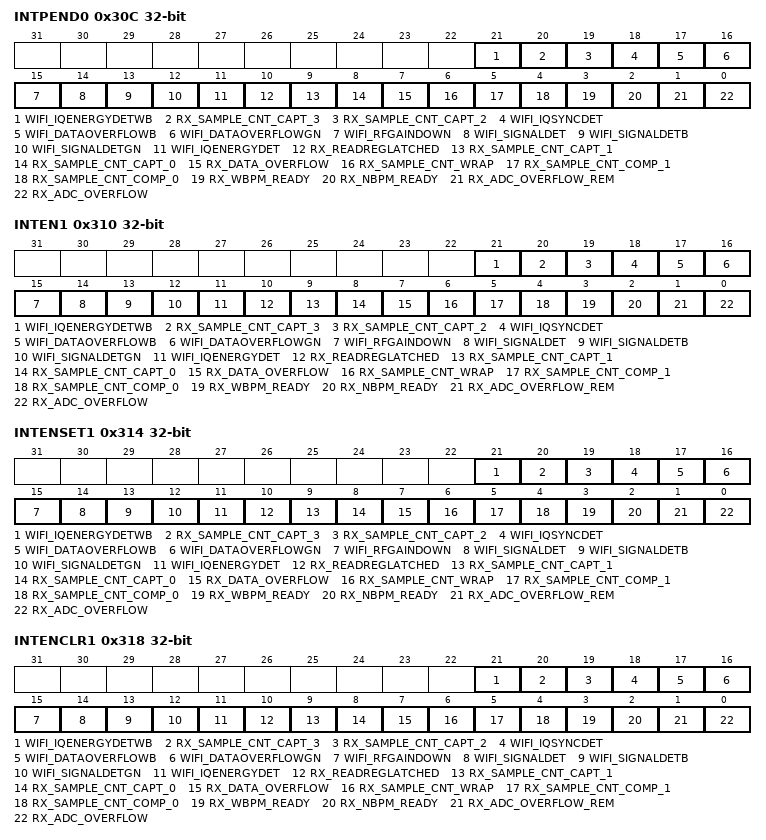
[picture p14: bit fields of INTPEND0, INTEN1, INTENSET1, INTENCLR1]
0x30C INTPEND0 ro — Pending interrupts
  [all] fields
    on read: 0=NotPending (Read: Not pending); 1=Pending (Read: Pending)
  [21] WIFI_IQENERGYDETWB — Read pending status of interrupt for event WIFI_IQENERGYDETWB
  [20] RX_SAMPLE_CNT_CAPT_3 — Read pending status of interrupt for event RX_SAMPLE_CNT_CAPT_3
  [19] RX_SAMPLE_CNT_CAPT_2 — Read pending status of interrupt for event RX_SAMPLE_CNT_CAPT_2
  [18] WIFI_IQSYNCDET — Read pending status of interrupt for event WIFI_IQSYNCDET
  [17] WIFI_DATAOVERFLOWB — Read pending status of interrupt for event WIFI_DATAOVERFLOWB
  [16] WIFI_DATAOVERFLOWGN — Read pending status of interrupt for event WIFI_DATAOVERFLOWGN
  [15] WIFI_RFGAINDOWN — Read pending status of interrupt for event WIFI_RFGAINDOWN
  [14] WIFI_SIGNALDET — Read pending status of interrupt for event WIFI_SIGNALDET
  [13] WIFI_SIGNALDETB — Read pending status of interrupt for event WIFI_SIGNALDETB
  [12] WIFI_SIGNALDETGN — Read pending status of interrupt for event WIFI_SIGNALDETGN
  [11] WIFI_IQENERGYDET — Read pending status of interrupt for event WIFI_IQENERGYDET
  [10] RX_READREGLATCHED — Read pending status of interrupt for event RX_READREGLATCHED
  [9] RX_SAMPLE_CNT_CAPT_1 — Read pending status of interrupt for event RX_SAMPLE_CNT_CAPT_1
  [8] RX_SAMPLE_CNT_CAPT_0 — Read pending status of interrupt for event RX_SAMPLE_CNT_CAPT_0
  [7] RX_DATA_OVERFLOW — Read pending status of interrupt for event RX_DATA_OVERFLOW
  [6] RX_SAMPLE_CNT_WRAP — Read pending status of interrupt for event RX_SAMPLE_CNT_WRAP
  [5] RX_SAMPLE_CNT_COMP_1 — Read pending status of interrupt for event RX_SAMPLE_CNT_COMP_1
  [4] RX_SAMPLE_CNT_COMP_0 — Read pending status of interrupt for event RX_SAMPLE_CNT_COMP_0
  [3] RX_WBPM_READY — Read pending status of interrupt for event RX_WBPM_READY
  [2] RX_NBPM_READY — Read pending status of interrupt for event RX_NBPM_READY
  [1] RX_ADC_OVERFLOW_REM — Read pending status of interrupt for event RX_ADC_OVERFLOW_REM
  [0] RX_ADC_OVERFLOW — Read pending status of interrupt for event RX_ADC_OVERFLOW
0x310 INTEN1 — Enable or disable interrupt
  fields as INTEN0
0x314 INTENSET1 — Enable interrupt
  fields as INTENSET0
0x318 INTENCLR1 — Disable interrupt
  fields as INTENCLR0
0x31C INTPEND1 ro — Pending interrupts
  fields as INTPEND0
0x400 RX_STATUS ro
  [1] WBPM_ACTIVE — Wide band power meter status.
    0=Inactive (WBPM inactive); 1=Active (WBPM active)
  [0] NBPM_ACTIVE — Narrow band power meter status.
    0=Inactive (NBPM inactive); 1=Active (NBPM active)
0x500 RX_DIG_ENABLE — RX digital enable
  [0] ENABLE — Enable RX digital.
    0=Disabled; 1=Enabled
0x504 RX_DATA_ENABLE
  [0] ENABLE — This bit controls the sync reset signal of the RX data interface.
    0=Disabled; 1=Enabled
0x510 RX_CLK_ENABLE reset 0x1 — RX data enable
  [0] ENABLE — This bit enables the RX data interface clock.
    0=Disabled; 1=Enabled
0x51C RX_CONFIGDONE — RX configuration done.
  [0] ENABLE — This bit indicates that RX digital has been configured. This bit must be asserted at the end of the configuration so that e.g. synchronization of registers to the core works correctly. This bit must be deasserted when RX digital is disabled.
    0=ConfNotDone (Configuration not done); 1=ConfDone (Configuration done)
0x520 RX_IQ_CONFIG — I/Q config
  [1] SWAP — Swaps I and Q paths with each other.
    0=NoSwap; 1=Swapped
  [0] EDGE — Defines on which edge of ADC clock to sample I and Q data.
    0=Falling edge; 1=Rising edge
0x524 RX_ADC_CK_REQ — RX ADC clock request
  [0] REQ — Requests ADC clock.
    0=NoRequest; 1=Request
0x528 RX_ADC_OVERFLOW — RX ADC overflow detection
  [11:7] FALL_LIMIT — Specifies how many ADC clock cycles are elapsed before overflow is removed.
    0=1cycle; 1=2cycles; 31=32cycles
  [6:1] RISE_LIMIT — Specifies how many consecutive cycles with +2 or -2 value must be detected on ADC data input before overflow is detected.
    0=1cycle; 1=2cycles; 63=64cycles
  [0] ENABLE — Enable ADC overflow detection logic.
    0=Disabled; 1=Enabled
0x52C RX_DEC_CONFIG reset 0x6 — RX decimation config
  [4:3] DATA_DOWNSAMPLE — Downsample selection of RX data output.
    0=Disabled; 1=DownsampleBy2; 2=DownsampleBy4; 3=DownsampleBy8
  [2] HBFIR2_ENABLE — Enable half-band FIR with decimation by 2.
    0=Disabled (Disable (i.e. bypass)); 1=Enabled
  [1] DECR_ENABLE — Enable CIC filter with decimation by factor R. R is 5 when normal decimation mode is selected and 4 when alternative decimation mode is selected.
    0=Disabled (Disable (i.e. bypass)); 1=Enabled
  [0] DEC2_ENABLE — Enable CIC filter with decimation by 2.
    0=Disabled (Disable (i.e. bypass)); 1=Enabled
0x530 RX_ALT_DEC_MODE — Alternative decimation mode.
  [0] MODE — Alternative decimation mode selection.
    0=Normal mode; 1=Alternative mode
0x534 RX_DCCOMP_HOLD — DC offset compensation hold
  [0] HOLD — With this bit, the DC estimation LPF can be put into hold mode.
    0=Running; 1=Hold
0x538 RX_DCCOMP_SEL — DC offset compensation selection
  [1:0] SEL — Selection of DC value removal.
    0=Internal (estimated) DC value subtracted from output; 1=External (register) DC value subtracted from output; 2=Bypassed (DC compensation is bypassed.)
0x53C RX_DCCOMP_COEFF_N — Coefficient N value of DC estimation LPF.
  [3:0] COEFF_N — Coefficient N value of DC estimation LPF. This value can be updated while RX digital is active.
0x540 RX_DCCOMP_INIT_I — Initialization value of DC I estimation LPF.
  [16:0] INIT — Initialization value (signed) of DC I estimation LPF. Taken into use when RX digital is activated. This value can be updated while RX digital is active.
0x544 RX_DCCOMP_INIT_Q — Initialization value of DC Q estimation LPF.
  [16:0] INIT — Initialization value (signed) of DC Q estimation LPF. Taken into use when RX digital is activated. This value can be updated while RX digital is active.
0x548 RX_DCCOMP_EXT_I — External value of DC I offset compensation.
  [16:0] EXT — External value (signed) of DC I offset compensation. This value is used when external DC estimation is selected by RX_DCCOMP_SEL register and can be updated while RX digital is active.
0x54C RX_DCCOMP_EXT_Q — External value of DC Q offset compensation.
  [16:0] EXT — External value (signed) of DC Q offset compensation. This value is used when external DC estimation is selected by RX_DCCOMP_SEL register and can be updated while RX digital is active.
0x550 RX_DCCOMP_EST_I ro — Estimated DC I value from DC estimation LPF.
  [16:0] EST — Estimated DC I value (signed) from DC estimation LPF.
0x554 RX_DCCOMP_EST_Q ro — Estimated DC Q value from DC estimation LPF.
  [16:0] EST — Estimated DC Q value (signed) from DC estimation LPF.
0x558 RX_FIR1_COEFF_0 reset 0x7F23E906 — FIR 1 coefficients 0, 1, 2 and 3.
  [8n+7:8n] COEFF_{n} (n=0..3) — FIR 1 coefficient {n} (signed value).
0x55C RX_FIR1_COEFF_1 — FIR 1 coefficients 4, 5, 6 and 7.
  [8n-25:8n-32] COEFF_{n} (n=4..7) — FIR 1 coefficient {n} (signed value).
0x560 RX_FIR1_COEFF_2 — FIR 1 coefficients 8, 9, 10 and 11.
  [8n-57:8n-64] COEFF_{n} (n=8..11) — FIR 1 coefficient {n} (signed value).
0x564 RX_FIR1_COEFF_3 — FIR 1 coefficients 12, 13, 14 and 15.
  [8n-89:8n-96] COEFF_{n} (n=12..15) — FIR 1 coefficient {n} (signed value).
0x568 RX_FIR1_COEFF_4 — FIR 1 coefficients 16, 17, 18 and 19.
  [8n-121:8n-128] COEFF_{n} (n=16..19) — FIR 1 coefficient {n} (signed value).
0x56C RX_FIR1_TAP_SEL reset 0x105 — Number of taps used in FIR 1.
  [9:8] SHIFT — Shift-right the output bits of FIR 1 filter.
    {v}=ShiftBy{v+5} (Shift-right by {v+5}) (v=0..3)
  [5:0] SEL — Number of taps used in FIR 1. The maximum number of taps is 40.
    0=2taps; 1=3taps; 5=7taps; 15=17taps; 25=27taps; 37=39taps
0x570 RX_FIR2_ENABLE — FIR 2 enable.
  [0] ENABLE — Enable FIR 2 filter.
    0=Disabled (Disable (i.e. bypass)); 1=Enabled
0x574 RX_FIR2_COEFF_0 — FIR 2 coefficients 0, 1, 2 and 3.
  [8n+7:8n] COEFF_{n} (n=0..3) — FIR 2 coefficient {n} (signed value).
0x578 RX_FIR2_COEFF_1 — FIR 2 coefficients 4, 5, 6 and 7.
  [8n-25:8n-32] COEFF_{n} (n=4..7) — FIR 2 coefficient {n} (signed value).
0x57C RX_FIR2_COEFF_2 — FIR 2 coefficients 8, 9, 10 and 11.
  [8n-57:8n-64] COEFF_{n} (n=8..11) — FIR 2 coefficient {n} (signed value).
0x580 RX_FIR2_COEFF_3 — FIR 2 coefficient 12
  [7:0] COEFF_12 — FIR 2 coefficient 12 (signed value).
0x584 RX_FIR2_TAP_SEL reset 0x200 — Number of taps used in FIR 2.
  [9:8] SHIFT — Shift-right the output bits of FIR 2 filter.
    {v}=ShiftBy{v+5} (Shift-right by {v+5}) (v=0..3)
  [4:0] SEL — Number of taps used in FIR 2. The maximum number of taps is 26.
    0=2taps; 1=3taps; 5=7taps; 15=17taps; 24=26taps
0x588 RX_SCALER_FINE_GAIN — Scaler fine gain.
  [7:0] GAIN — Controls RX digital output fine gain, in ca. 0.034 dB steps. Total gain is sum of SCALER_FINE_GAIN and SCALER_COARSE_GAIN. This value can be updated while RX digital is active.
    0=0p000dB (+0.000 dB); 1=0p034dB (+0.034 dB); 2=0p068dB (+0.068 dB); 255=6p004dB (+6.004 dB)
0x58C RX_SCALER_COARSE_GAIN — Scaler coarse gain.
  [4:0] GAIN — Controls RX digital output coarse gain, in 6.02 dB steps. Total gain is sum of SCALER_FINE_GAIN and SCALER_COARSE_GAIN. This value can be updated while RX digital is active.
    0=m90p31dB (-90.31 dB); 1=m84p29dB (-84.29 dB); 14=m6p02dB (-6.02 dB); 15=0p00dB (+0.00 dB); 16=6p02dB (+6.02 dB); 30=90p31dB (+90.31 dB); 31=96p33dB (+96.33 dB)
0x590 RX_NBPM_DATA_SEL reset 0x1 — Narrow band power meter input data selection.
  [0] SEL — Selects input data of narrow band power meter.
    0=DecAndFilt (Decimation and filtering block output.); 1=Scaler output
0x594 RX_NBPM_FACTOR_L — Narrow band power meter input data selection.
  [2:0] FACTOR — Specifies how many bits of input data are downshifted before data is feed into narrow band power meter.
    0=0bit; 1=1bit; 7=7bits
0x598 RX_NBPM_FACTOR_M — Narrow band power meter factor M.
  [5:0] FACTOR — Number of consecutive power measurements on which max power is performed.
    0=1 measurement; 1=2 measurements; 63=64 measurements
0x59C RX_NBPM_FACTOR_K — Narrow band power meter factor K.
  [11:0] FACTOR — Number of samples considered in power and DC measurement (i.e. accumulation).
    0=1sample; 1=2samples; 0xFFF=4096samples
0x5A0 RX_NBPM_FACTOR_N — Narrow band power meter factor N.
  [3:0] FACTOR — Specifies how many bits are downshifted after power and DC accumulation.
    0=0bit; 1=1bit; 15=15bits
0x5A4 RX_NBPM_POWER ro — Measured narrow band power.
  [31:0] POWER — This is a squared value. This registers can be read after RX_NBPM_READY event is occurred.
